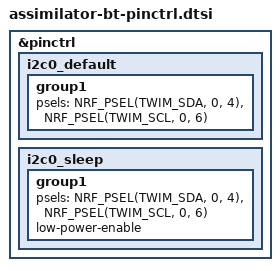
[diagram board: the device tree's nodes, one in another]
/*
 * Copyright (c) 2022 The ZMK Contributors
 * SPDX-License-Identifier: MIT
 */

&pinctrl {

    i2c0_default: i2c0_default {
        group1 {
            psels = <NRF_PSEL(TWIM_SDA, 0, 4)>,
                <NRF_PSEL(TWIM_SCL, 0, 6)>;
        };
    };

    i2c0_sleep: i2c0_sleep {
        group1 {
            psels = <NRF_PSEL(TWIM_SDA, 0, 4)>,
                <NRF_PSEL(TWIM_SCL, 0, 6)>;
            low-power-enable;
        };
    };
};
